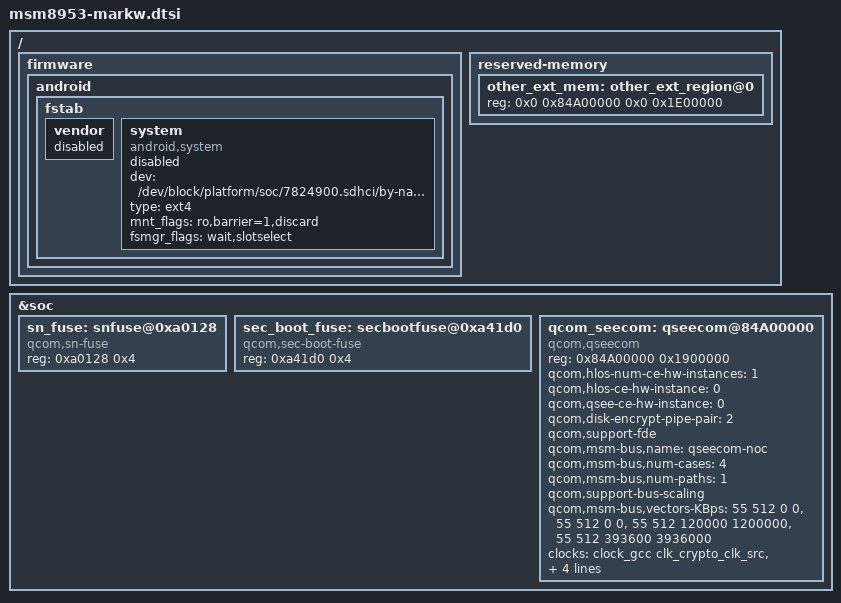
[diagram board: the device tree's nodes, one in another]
/*
 * Copyright (c) 2015-2018, The Linux Foundation. All rights reserved.
 *
 * This program is free software; you can redistribute it and/or modify
 * it under the terms of the GNU General Public License version 2 and
 * only version 2 as published by the Free Software Foundation.
 *
 * This program is distributed in the hope that it will be useful,
 * but WITHOUT ANY WARRANTY; without even the implied warranty of
 * MERCHANTABILITY or FITNESS FOR A PARTICULAR PURPOSE.  See the
 * GNU General Public License for more details.
 */

#include <dt-bindings/clock/msm-clocks-8953.h>
#include <dt-bindings/regulator/qcom,rpm-smd-regulator.h>
#include <dt-bindings/gpio/gpio.h>

/ {
	firmware: firmware {
		android {
			fstab {
				vendor {
					status = "disable";
				};
				system {
					compatible = "android,system";
					dev = "/dev/block/platform/soc/7824900.sdhci/by-name/system";
					type = "ext4";
					mnt_flags = "ro,barrier=1,discard";
					fsmgr_flags = "wait,slotselect";
					status = "disable";
				};

			};
		};
	};
	reserved-memory {
		other_ext_mem: other_ext_region@0 {
			reg = <0x0 0x84A00000 0x0 0x1E00000>;
		};
	};
};

&soc {
	sn_fuse: snfuse@0xa0128 {
		compatible = "qcom,sn-fuse";
		reg = <0xa0128 0x4>;
		reg-names = "sn-base";
	};
 	sec_boot_fuse: secbootfuse@0xa41d0 {
		compatible = "qcom,sec-boot-fuse";
		reg = <0xa41d0 0x4>;
		reg-names = "sec-boot-base";
	};
	/delete-node/ qseecom@85b00000;
	qcom_seecom: qseecom@84A00000 {
		compatible = "qcom,qseecom";
		reg = <0x84A00000 0x1900000>;
		reg-names = "secapp-region";
		qcom,hlos-num-ce-hw-instances = <1>;
		qcom,hlos-ce-hw-instance = <0>;
		qcom,qsee-ce-hw-instance = <0>;
		qcom,disk-encrypt-pipe-pair = <2>;
		qcom,support-fde;
		qcom,msm-bus,name = "qseecom-noc";
		qcom,msm-bus,num-cases = <4>;
		qcom,msm-bus,num-paths = <1>;
		qcom,support-bus-scaling;
		qcom,msm-bus,vectors-KBps =
			<55 512 0 0>,
			<55 512 0 0>,
			<55 512 120000 1200000>,
			<55 512 393600 3936000>;
		clocks = <&clock_gcc clk_crypto_clk_src>,
			 <&clock_gcc clk_gcc_crypto_clk>,
			 <&clock_gcc clk_gcc_crypto_ahb_clk>,
			 <&clock_gcc clk_gcc_crypto_axi_clk>;
		clock-names = "core_clk_src", "core_clk",
				"iface_clk", "bus_clk";
		qcom,ce-opp-freq = <100000000>;
	};
};
